# psoc6_01 register map
Vendor: Infineon Technologies; Series: PSOC6_01; File version: 1.0
CPU: CM4 r0p1, little endian, MPU, FPU, VTOR, 3 interrupt priority bits
Registers are 32-bit, read-write, reset 0x0 unless marked. A register's access mark holds for its fields unless they carry their own. Offsets are from the block's base; [hi:lo] are bit positions; {n}, {i} and the like mark numbered series; 'fields as' and 'values as' point back to an identical list.

## PDM0 — PDM registers
Base 0x42A20000
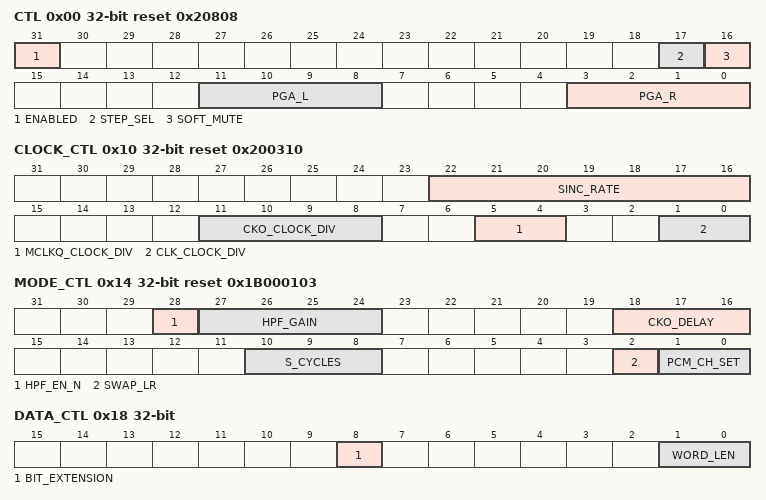
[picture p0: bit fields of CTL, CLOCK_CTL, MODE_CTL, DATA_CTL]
0x00 CTL reset 0x20808 — Control
  [31] ENABLED — Enables the PDM component: '0': Disabled. '1': Enabled.
  [17] STEP_SEL — Set fine gain step for smooth PGA or Soft-Mute attenuation transition. '0': 0.13dB '1': 0.26dB (Note: This bit is connected to AR36U12.PDM_CORE2_CFG.SEL_STEP)
  [16] SOFT_MUTE — Soft mute function to mute the volume smoothly '0': Disabled. '1': Enabled. (Note: This bit is connected to AR36U12.PDM_CORE_CFG.SOFT_MUTE)
  [11:8] PGA_L — Left channel PGA gain: +1.5dB/step, -12dB ~ +10.5dB '0': -12 dB '1': -10.5 dB ... '15': +10.5 dB (Note: These bits are connected to AR36U12.PDM_CORE_CFG.PGA_L)
  [3:0] PGA_R — Right channel PGA gain: +1.5dB/step, -12dB ~ +10.5dB '0': -12 dB '1': -10.5 dB ... '15' +10.5 dB (Note: These bits are connected to AR36U12.PDM_CORE_CFG.PGA_R)
0x10 CLOCK_CTL reset 0x200310 — Clock control
  [22:16] SINC_RATE — SINC Decimation Rate. For details, see the data sheet provided by Archband. Oversampling Ratio = Decimation Rate = 2 X SINC_RATE (Note: These bits are connected to AR36U12.PDM_CORE_CFG.SINC_RATE)
  [11:8] CKO_CLOCK_DIV — PDM CKO (FPDM_CKO) clock divider (3rd divider): FPDM_CKO = MCLKQ / (CKO_CLOCK_DIV + 1) Note: To configure '0' to this field is prohibited. (Note: PDM_CKO is configured by MCLKQ_CLOCK_DIV, CLK_CLOCK_DIV and CKO_CLOCK_DIV. ) (Note: These bits are connected to AR36U12.PDM_CORE_CFG.MCLKDIV)
  [5:4] MCLKQ_CLOCK_DIV — MCLKQ divider (2nd divider) (Note: These bits are connected to AR36U12.PDM_CORE2_CFG.DIV_MCLKQ)
    0=DIVBY1 (Divide by 1); 1=DIVBY2 (Divide by 2 (no 50 percent duty cycle)); 2=DIVBY3 (Divide by 3 (no 50 percent duty cycle)); 3=DIVBY4 (Divide by 4 (no 50 percent duty cycle))
  [1:0] CLK_CLOCK_DIV — PDM CLK (FPDM_CLK) (1st divider): This configures a frequency of PDM CLK. The configured frequency is used to operate PDM core. I.e. the frequency is input to MCLKQ_CLOCK_DIV register. Note: configure a frequency of PDM CLK as lower than or equal 50MHz with this divider.
    values as MCLKQ_CLOCK_DIV
0x14 MODE_CTL reset 0x1B000103 — Mode control
  [28] HPF_EN_N — Enable high pass filter (active low) '1': Disabled. '0': Enabled. (Note: This bit is connected to AR36U12.PDM_CORE_CFG.ADCHPD)
  [27:24] HPF_GAIN — Adjust high pass filter coefficients. H(Z) = (1 - Z-1 ) / [1 - (1- 2 -HPF_GAIN) Z-1 ] (Note: These bits are connected to AR36U12.PDM_CORE_CFG.HPGAIN)
  [18:16] CKO_DELAY — Phase difference from the rising edge of internal sampler clock (CLK_IS) to that of PDM_CKO clock: (Note: These bits are connected to AR36U12.PDM_CORE2_CFG.PDMCKO_DLY)
    0=ADV3 (CLK_IS is 3*PDM_CLK period early); 1=ADV2 (CLK_IS is 2*PDM_CLK period early); 2=ADV1 (CLK_IS is 1*PDM_CLK period early); 3=NO_DELAY (CLK_IS is the same as PDM_CKO); {v}=DLY{v-3} (CLK_IS is {v-3}*PDM_CLK period late) (v=4..7)
  [10:8] S_CYCLES — Set time step for gain change during PGA or soft mute operation in number of 1/a sampling rate. (Note: These bits are connected to AR36U12.PDM_CORE_CFG.S_CYCLES)
    0=STEP_NUM64 (64steps); 1=STEP_NUM96 (96steps); 2=STEP_NUM128 (128steps); 3=STEP_NUM160 (160steps); 4=STEP_NUM192 (192steps); 5=STEP_NUM256 (256steps); 6=STEP_NUM384 (384steps); 7=STEP_NUM512 (512steps)
  [2] SWAP_LR — Input data L/R channel swap: '1': Right/Left channel recording swap '0': No Swap (Note: This bit is connected to AR36U12.PDM_CORE_CFG.LRSWAP)
  [1:0] PCM_CH_SET — Specifies PCM output channels as mono or stereo: (Note: These bits are connected to AR36U12.PDM_CORE2_CFG.PCM_CHSET)
    0=DISABLED (Channel disabled); 1=MONO_L (Mono left channel enable); 2=MONO_R (Mono right channel enable); 3=STEREO (Stereo channel enable)
0x18 DATA_CTL — Data control
  [8] BIT_EXTENSION — When reception word length is shorter than the word length of RX_FIFO_RD, extension mode of upper bit should be set. '0': Extended by '0' '1': Extended by sign bit (if MSB word is '1', then it is extended by '1', if MSB is '0' then it is extended by '0')
  [1:0] WORD_LEN — PCM Word Length in number of bits: (Note: These bits are connected to AR36U12.PDM_CORE2_CFG.PCM_IWL)
    0=BIT_LEN16 (16-bit); 1=BIT_LEN18 (18-bit); 2=BIT_LEN20 (20-bit); 3=BIT_LEN24 (24-bit)
0x20 CMD — Command
  [0] STREAM_EN — Enable data streaming flow: '0': Disabled. '1': Enabled. (Note: This bit is connected to AR36U12.PDM_CORE_CFG.PDMA_EN)
0x40 TR_CTL — Trigger control
  [16] RX_REQ_EN — Trigger output ('tr_pdm_rx_req') enable for requests of DMA transfer '0': Disabled. '1': Enabled.
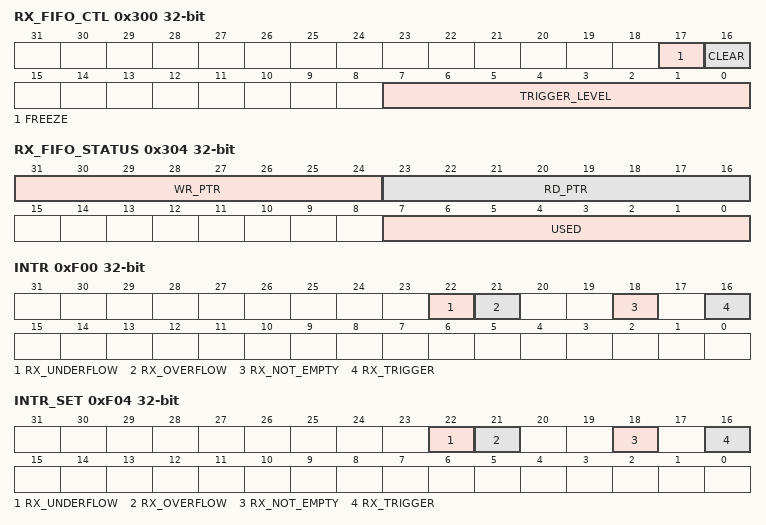
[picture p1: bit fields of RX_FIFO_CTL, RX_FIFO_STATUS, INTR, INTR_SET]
0x300 RX_FIFO_CTL — RX FIFO control
  [17] FREEZE — When '1', hardware writes to the RX FIFO have no effect. Freeze will not advance the RX FIFO write pointer.This field is used only for debugging purposes.
  [16] CLEAR — When '1', the RX FIFO and RX_BUF are cleared/invalidated. Invalidation will last for as long as this field is '1'. If a quick clear/invalidation is required, the field should be set to '1' and be followed by a set to '0'. If a clear/invalidation is required for an extended time period, the field should be set to '1' during the complete time period.
  [7:0] TRIGGER_LEVEL — Trigger level. When the RX FIFO has more entries than the number of this field, a receiver trigger event is generated. Note: software can configure up to 254 in Mono channel enabled (MODE_CTL.PCM_CH_SET = '1' or '2'), up to 253 in Stereo channel enabled (MODE_CTL.PCM_CH_SET = '3').
0x304 RX_FIFO_STATUS ro
  [31:24] WR_PTR — RX FIFO write pointer: RX FIFO location at which a new data frame is written by the hardware.This field is used only for debugging purposes.
  [23:16] RD_PTR — RX FIFO read pointer: RX FIFO location from which a data frame is read by the host.This field is used only for debugging purposes.
  [7:0] USED — Number of entries in the RX FIFO. The field value is in the range [0, 255]. When this is zero, the RX FIFO is empty.
0x308 RX_FIFO_RD ro — RX FIFO read
  [31:0] DATA — Data read from the RX FIFO. Reading a data frame will remove the data frame from the FIFO; i.e. behavior is similar to that of a POP operation. Note: Don't access to this bit while RX_FIFO_CTL.CLEAR is '1'.
0x30C RX_FIFO_RD_SILENT ro — RX FIFO silent read
  [31:0] DATA — Data read from the RX FIFO. Reading a data frame will NOT remove the data frame from the RX FIFO; i.e. behavior is similar to that of a PEEK operation. This field is used only for debugging purposes. Note: Don't access to this bit while RX_FIFO_CTL.CLEAR is '1'.
0xF00 INTR — Interrupt register
  [22] RX_UNDERFLOW — Attempt to read from an empty RX FIFO
  [21] RX_OVERFLOW — Attempt to write to a full RX FIFO
  [18] RX_NOT_EMPTY — RX FIFO is not empty.
  [16] RX_TRIGGER — More entries in the RX FIFO than the value specified by TRIGGER_LEVEL in RX_FIFO_CTL.
0xF04 INTR_SET — Interrupt set register
  [22] RX_UNDERFLOW — Write with '1' to set corresponding bit in interrupt request register.
  [21] RX_OVERFLOW — Write with '1' to set corresponding bit in interrupt request register.
  [18] RX_NOT_EMPTY — Write with '1' to set corresponding bit in interrupt request register.
  [16] RX_TRIGGER — Write with '1' to set corresponding bit in interrupt request register.
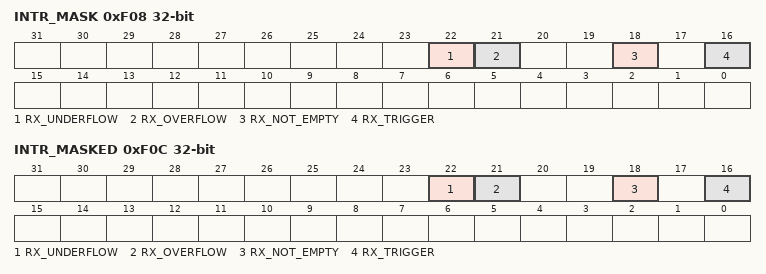
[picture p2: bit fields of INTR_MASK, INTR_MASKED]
0xF08 INTR_MASK — Interrupt mask register
  [22] RX_UNDERFLOW — Mask bit for corresponding bit in interrupt request register.
  [21] RX_OVERFLOW — Mask bit for corresponding bit in interrupt request register.
  [18] RX_NOT_EMPTY — Mask bit for corresponding bit in interrupt request register.
  [16] RX_TRIGGER — Mask bit for corresponding bit in interrupt request register.
0xF0C INTR_MASKED ro — Interrupt masked register
  [22] RX_UNDERFLOW — Logical and of corresponding request and mask bits.
  [21] RX_OVERFLOW — Logical and of corresponding request and mask bits.
  [18] RX_NOT_EMPTY — Logical and of corresponding request and mask bits.
  [16] RX_TRIGGER — Logical and of corresponding request and mask bits.
